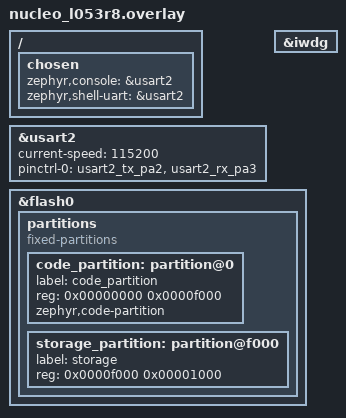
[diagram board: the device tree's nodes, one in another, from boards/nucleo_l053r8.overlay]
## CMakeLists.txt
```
cmake_minimum_required(VERSION 3.20.0)

if (BOARD STREQUAL "nucleo_l053r8")
  set(DTC_OVERLAY_FILE
      ${CMAKE_CURRENT_SOURCE_DIR}/boards/nucleo_l053r8.overlay
      ${CMAKE_CURRENT_SOURCE_DIR}/boards/nucleo_l053r8_app.overlay)
endif()

find_package(Zephyr REQUIRED HINTS $ENV{ZEPHYR_BASE})
project(led_threads)

# Add app sources explicitly
target_sources(app PRIVATE
  src/main.c
  src/supervisor.c
  src/recovery.c
  src/persist_state.c
  src/uart_commands.c
  src/watchdog_ctrl.c
)

# Allow #include "supervisor.h" etc without full path (autocomplete)
target_include_directories(app PRIVATE ${CMAKE_CURRENT_SOURCE_DIR}/src)
```

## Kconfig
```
menu "LED Threads Application"

config APP_WATCHDOG_BOOT_TIMEOUT_MS
	int "Boot watchdog timeout (ms)"
	default 8000
	range 100 60000
	help
	  Initial watchdog timeout applied during system startup. Use a large
	  value to cover expensive init sequences.

config APP_WATCHDOG_STEADY_TIMEOUT_MS
	int "Steady-state watchdog timeout (ms)"
	default 2000
	range 100 60000
	help
	  Watchdog timeout that the supervisor applies once the system has
	  reached its steady state.

config APP_WATCHDOG_RETUNE_DELAY_MS
	int "Delay before watchdog retune (ms)"
	default 5000
	range 0 60000
	help
	  Duration after boot before the watchdog is tightened to the
	  steady-state timeout.

config APP_RESET_WATCHDOG_THRESHOLD
	int "Watchdog reset storm threshold"
	default 3
	range 1 20
	help
	  Number of consecutive watchdog resets that triggers fallback mode.

config APP_HEALTH_LED_STALE_MS
	int "LED heartbeat stale threshold (ms)"
	default 1500
	range 100 10000
	help
	  Maximum allowed age of the LED thread heartbeat before it is
	  considered stale.

config APP_HEALTH_SYS_STALE_MS
	int "System heartbeat stale threshold (ms)"
	default 1500
	range 100 10000
	help
	  Maximum allowed age of the system heartbeat before it is
	  considered stale.

config APP_ENABLE_UART_COMMANDS
	bool "Enable UART command handler"
	default y
	help
	  Enable a minimal UART command parser for runtime configuration of
	  watchdog parameters. Disable if RAM usage is too tight.

config APP_SAFE_MODE_REBOOT_DELAY_MS
	int "Safe-mode auto reboot delay (ms)"
	default 60000
	range 0 300000
	help
	  When fallback (safe) mode is entered, schedule an automatic warm
	  reboot after this many milliseconds. Set to 0 to keep the system in
	  safe mode indefinitely.

endmenu

source "Kconfig.zephyr"
```

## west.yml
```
manifest:
  defaults:
    remote: zephyrproject-rtos
  remotes:
    - name: zephyrproject-rtos
      url-base: https://github.com/zephyrproject-rtos
  projects:
    - name: zephyr
      revision: v4.2.0
      import: true
  self:
    path: .
```

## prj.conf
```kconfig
# ==== Core stacks ====
CONFIG_MAIN_STACK_SIZE=1568
CONFIG_ISR_STACK_SIZE=1024
CONFIG_IDLE_STACK_SIZE=320

# ==== Storage / persistence ====
# Flash/NVS requires flash driver enabled explicitly on this part
CONFIG_FLASH=y
CONFIG_FLASH_PAGE_LAYOUT=y
CONFIG_FLASH_MAP=y
CONFIG_NVS=y

# ---- Console / Serial ----
CONFIG_CONSOLE=y
CONFIG_UART_CONSOLE=y
CONFIG_SERIAL=y
CONFIG_THREAD_NAME=y

# ---- Logging to UART (no printk routing) ----
CONFIG_LOG=y
CONFIG_LOG_BACKEND_UART=y
CONFIG_LOG_MODE_IMMEDIATE=y        # immediate = safest on tiny MCUs
CONFIG_LOG_DEFAULT_LEVEL=3

# Keep printk enabled if the board wants it, but don't route printk into LOG
CONFIG_LOG_PRINTK=n

# ---- Drivers ----
CONFIG_GPIO=y
CONFIG_HWINFO=y                    # for hwinfo_get_reset_cause()

#our code will control wdg, not default setup
CONFIG_WDT_DISABLE_AT_BOOT=y
CONFIG_WATCHDOG=y

# ---- Fault dump (replace any FATAL_EXCEPTION_DUMP usage) ----
CONFIG_FAULT_DUMP=1              

# Enable reboot & system management
CONFIG_REBOOT=y

# Application tuning
CONFIG_APP_WATCHDOG_BOOT_TIMEOUT_MS=8000
CONFIG_APP_WATCHDOG_STEADY_TIMEOUT_MS=2000
CONFIG_APP_WATCHDOG_RETUNE_DELAY_MS=5000
CONFIG_APP_RESET_WATCHDOG_THRESHOLD=3
CONFIG_APP_HEALTH_LED_STALE_MS=1500
CONFIG_APP_HEALTH_SYS_STALE_MS=1500
CONFIG_APP_ENABLE_UART_COMMANDS=n
CONFIG_APP_SAFE_MODE_REBOOT_DELAY_MS=60000

# Thread configuration
CONFIG_THREAD_MONITOR=y
CONFIG_THREAD_STACK_INFO=y

# Recovery + supervisor require event support
CONFIG_EVENTS=y
```

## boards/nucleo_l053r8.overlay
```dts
/{
	chosen{
		zephyr,console=&usart2;
		zephyr,shell-uart=&usart2;
	};
};
&usart2{ 
	status="okay"; current-speed = <115200>; 
	pinctrl-0 = < &usart2_tx_pa2 &usart2_rx_pa3>; pinctrl-names = "default";
};


/*Enable STM32 Independent Watchdog (IWDG)*/
&iwdg{
	status="okay";
};

&flash0 {
	partitions {
		compatible = "fixed-partitions";
		#address-cells = <1>;
		#size-cells = <1>;

		code_partition: partition@0 {
			label = "code_partition";
			reg = <0x00000000 0x0000f000>;
			zephyr,code-partition;
		};

		storage_partition: partition@f000 {
			label = "storage";
			reg = <0x0000f000 0x00001000>;
		};
	};
};
```

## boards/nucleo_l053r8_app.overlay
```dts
&code_partition {
	/delete-property/ zephyr,code-partition;
};

/ {
	chosen {
		zephyr,code-partition = &code_partition;
	};
};
```

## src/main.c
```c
/* main.c - NUCLEO-L053R8: LED + Heartbeat + Watchdog (STM32 IWDG) */
#include <zephyr/drivers/gpio.h>
#include <zephyr/drivers/hwinfo.h>
#include <zephyr/kernel.h>
#include <zephyr/logging/log.h>
#include <zephyr/sys/util.h>
#include <stdint.h>

#include "log_utils.h"
#include "persist_state.h"
#include "recovery.h"
#include "supervisor.h"
#include "uart_commands.h"
#include "watchdog_ctrl.h"

LOG_MODULE_REGISTER(app, LOG_LEVEL_INF);

/* -------- LED: via devicetree alias 'led0' -------- */
#define LED0_NODE DT_ALIAS(led0)
#if !DT_NODE_HAS_STATUS(LED0_NODE, okay)
#error "Unsupported board: led0 devicetree alias is not defined"
#endif
static const struct gpio_dt_spec led = GPIO_DT_SPEC_GET(LED0_NODE, gpios);

/* Optional reset cause printout */
static uint32_t log_reset_cause(void)
{
	uint32_t cause = 0;
	if (hwinfo_get_reset_cause(&cause) == 0) {
		if (cause & RESET_WATCHDOG) LOG_WRN("Reset cause: WATCHDOG");
		if (cause & RESET_SOFTWARE) LOG_WRN("Reset cause: SOFTWARE");
		if (cause & RESET_POR)      LOG_WRN("Reset cause: POWER-ON");
		hwinfo_clear_reset_cause();
	}
	return cause;
}

/* -------- Threads -------- */
K_THREAD_STACK_DEFINE(health_stack, 704);
static struct k_thread health_tid;

static void health_thread(void *p1, void *p2, void *p3)
{
	bool fallback_mode = (bool)(uintptr_t)p1;
	ARG_UNUSED(p2);
	ARG_UNUSED(p3);
	k_thread_name_set(k_current_get(),
			      fallback_mode ? "health (fallback)" : "health");

	int ret = gpio_pin_configure_dt(&led, GPIO_OUTPUT_INACTIVE);
	if (ret) {
		LOG_ERR("LED config failed: %d", ret);
		return;
	}

	if (fallback_mode) {
		LOG_EVT_SIMPLE(WRN, "SAFE_MODE", "LED_SLOW_BLINK");
	}

	const uint32_t led_period_ms = fallback_mode ? 1000U : 500U;
	const uint32_t heartbeat_period_ms = 1000U;
	uint32_t hb_elapsed = 0U;
	uint32_t heartbeat_counter = 0U;

	while (1) {
		ret = gpio_pin_toggle_dt(&led);
		if (ret) {
			LOG_ERR("LED toggle failed: %d", ret);
			k_msleep(1000);
			continue;
		}

		supervisor_notify_led_alive();

		hb_elapsed += led_period_ms;
		if (hb_elapsed >= heartbeat_period_ms) {
			hb_elapsed -= heartbeat_period_ms;
			supervisor_notify_system_alive();
			heartbeat_counter++;

		if ((heartbeat_counter % 10U) == 0U) {
			LOG_EVT(INF, "HEARTBEAT", "OK", "count=%u", heartbeat_counter);
		}
		}

		k_msleep(led_period_ms);
	}
}

void main(void)
{
	k_thread_name_set(k_current_get(), "main");
	LOG_EVT_SIMPLE(INF, "APP", "START");

	int ret = persist_state_init();
	if (ret) {
		LOG_ERR("Persistent state init failed: %d", ret);
	}

	uint32_t reset_cause = log_reset_cause();
	bool watchdog_reset = (reset_cause & RESET_WATCHDOG) != 0U;
	persist_state_record_boot(watchdog_reset);

	uint32_t consecutive = persist_state_get_consecutive_watchdog();
	if (consecutive != 0U) {
		LOG_EVT(WRN, "WATCHDOG", "RESET_HISTORY",
			"consecutive=%u,total=%u", consecutive, persist_state_get_total_watchdog());
	}

	bool fallback_mode = persist_state_is_fallback_active();
	if (fallback_mode) {
		LOG_EVT_SIMPLE(ERR, "SAFE_MODE", "ENTERED");
		persist_state_clear_watchdog_counter();
		LOG_EVT_SIMPLE(INF, "WATCHDOG", "COUNTER_CLEARED");
	}

	recovery_start();
	recovery_schedule_safe_mode_reboot(
		fallback_mode ? CONFIG_APP_SAFE_MODE_REBOOT_DELAY_MS : 0U);

	uint32_t boot_timeout_ms = CONFIG_APP_WATCHDOG_BOOT_TIMEOUT_MS;
	uint32_t steady_timeout_ms = persist_state_get_watchdog_override();
	if (steady_timeout_ms == 0U) {
		steady_timeout_ms = CONFIG_APP_WATCHDOG_STEADY_TIMEOUT_MS;
	}
	uint32_t retune_delay_ms = CONFIG_APP_WATCHDOG_RETUNE_DELAY_MS;

	if (fallback_mode) {
		steady_timeout_ms = MAX(steady_timeout_ms, boot_timeout_ms);
		retune_delay_ms = 0U;
	}

	ret = watchdog_ctrl_init(boot_timeout_ms);
	if (ret) {
		LOG_EVT(ERR, "WATCHDOG", "INIT_FAIL", "rc=%d", ret);
		LOG_EVT_SIMPLE(ERR, "RECOVERY", "WATCHDOG_INIT_FAIL");
		recovery_request(RECOVERY_REASON_WATCHDOG_INIT_FAIL);
		return;
	}

	LOG_EVT(INF, "WATCHDOG", "CONFIGURED",
		"boot_ms=%u,steady_ms=%u,retune_delay_ms=%u", boot_timeout_ms,
		steady_timeout_ms, retune_delay_ms);
	if (fallback_mode) {
		LOG_EVT_SIMPLE(WRN, "WATCHDOG", "RETUNE_DISABLED_SAFE_MODE");
	}

	k_thread_create(&health_tid, health_stack, K_THREAD_STACK_SIZEOF(health_stack),
			health_thread, (void *)(uintptr_t)fallback_mode,
			NULL, NULL, 5, 0, K_NO_WAIT);
	k_thread_name_set(&health_tid, fallback_mode ?
			       "Health Thread (fallback)" : "Health Thread");

	supervisor_start(steady_timeout_ms, retune_delay_ms, !fallback_mode);

	if (IS_ENABLED(CONFIG_APP_ENABLE_UART_COMMANDS)) {
		uart_commands_start(fallback_mode);
	}

	/* small delay to let logging flush before threads settle */
	k_msleep(120);

	LOG_EVT_SIMPLE(INF, "APP", "READY");

}
```

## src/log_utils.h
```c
#pragma once

#include <zephyr/logging/log.h>

/* Compact structured logging helpers.
 * Format: EVT,<tag>,<status>[,<kv pairs...>]
 */
#define LOG_EVT_SIMPLE(level, tag, status) \
	LOG_##level("EVT,%s,%s", tag, status)

#define LOG_EVT(level, tag, status, fmt, ...) \
	LOG_##level("EVT,%s,%s," fmt, tag, status, ##__VA_ARGS__)
```

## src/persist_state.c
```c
#include "persist_state.h"
#include "log_utils.h"

#include <errno.h>
#include <string.h>

#include <zephyr/device.h>
#include <zephyr/drivers/flash.h>
#include <zephyr/kernel.h>
#include <zephyr/logging/log.h>
#include <zephyr/storage/flash_map.h>
#include <zephyr/fs/nvs.h>

LOG_MODULE_REGISTER(persist_state, LOG_LEVEL_INF);

#define PERSIST_MAGIC 0x4C454452u /* 'LEDR' */
#define PERSIST_RECORD_ID 1

#define STORAGE_PARTITION_NODE DT_NODELABEL(storage_partition)
#define PERSIST_RETRY_LIMIT 3
#define PERSIST_RETRY_DELAY_MS 10

struct persist_blob {
	uint32_t magic;
	uint32_t consecutive_watchdog;
	uint32_t total_watchdog;
	uint32_t watchdog_override_ms;
};

static struct {
	struct nvs_fs fs;
	struct persist_blob blob;
	bool loaded;
} g_state;

static K_MUTEX_DEFINE(state_lock);

static int persist_commit_locked(void)
{
	int rc = nvs_write(&g_state.fs, PERSIST_RECORD_ID,
			   &g_state.blob, sizeof(g_state.blob));

	if (rc < 0) {
		LOG_ERR("Persistent write failed: %d", rc);
		LOG_EVT(ERR, "PERSIST", "WRITE_FAIL", "rc=%d", rc);
		return rc;
	}

	return 0;
}

static int init_fs_if_needed(void)
{
	if (g_state.loaded) {
		return 0;
	}

	const struct flash_area *fa = NULL;
	int rc = 0;

	for (int attempt = 1; attempt <= PERSIST_RETRY_LIMIT; ++attempt) {
		rc = flash_area_open(DT_FIXED_PARTITION_ID(STORAGE_PARTITION_NODE), &fa);
		if (rc == 0) {
			if (attempt > 1) {
				LOG_EVT(INF, "PERSIST", "FLASH_OPEN_RECOVERED", "attempt=%d", attempt);
			}
			break;
		}

		LOG_WRN("Failed to open storage partition (attempt %d/%d): %d",
			attempt, PERSIST_RETRY_LIMIT, rc);
		LOG_EVT(WRN, "PERSIST", "FLASH_OPEN_RETRY", "attempt=%d,rc=%d", attempt, rc);

		if (attempt < PERSIST_RETRY_LIMIT) {
			k_msleep(PERSIST_RETRY_DELAY_MS);
		}
	}

	if (rc != 0) {
		LOG_EVT(ERR, "PERSIST", "FLASH_OPEN_FAIL", "rc=%d", rc);
		return rc;
	}

	g_state.fs.flash_device = fa->fa_dev;
	if (!device_is_ready(g_state.fs.flash_device)) {
		LOG_ERR("Storage flash device not ready");
		LOG_EVT(ERR, "PERSIST", "FLASH_NOT_READY", "dev_id=%u",
			DT_FIXED_PARTITION_ID(STORAGE_PARTITION_NODE));
		flash_area_close(fa);
		return -EBUSY;
	}

	g_state.fs.offset = fa->fa_off;

	struct flash_pages_info page_info;
	rc = flash_get_page_info_by_offs(g_state.fs.flash_device,
					 g_state.fs.offset, &page_info);
	if (rc != 0) {
		LOG_ERR("flash_get_page_info_by_offs failed: %d", rc);
		LOG_EVT(ERR, "PERSIST", "FLASH_PAGE_INFO_FAIL", "rc=%d", rc);
		flash_area_close(fa);
		return rc;
	}

	g_state.fs.sector_size = page_info.size;
	g_state.fs.sector_count = fa->fa_size / page_info.size;

	flash_area_close(fa);

	for (int attempt = 1; attempt <= PERSIST_RETRY_LIMIT; ++attempt) {
		rc = nvs_mount(&g_state.fs);
		if (rc == 0) {
			if (attempt > 1) {
				LOG_EVT(INF, "PERSIST", "NVS_MOUNT_RECOVERED", "attempt=%d", attempt);
			}
			break;
		}

		LOG_WRN("Failed to mount NVS (attempt %d/%d): %d",
			attempt, PERSIST_RETRY_LIMIT, rc);
		LOG_EVT(WRN, "PERSIST", "NVS_MOUNT_RETRY", "attempt=%d,rc=%d", attempt, rc);

		if (attempt < PERSIST_RETRY_LIMIT) {
			k_msleep(PERSIST_RETRY_DELAY_MS);
		}
	}

	if (rc != 0) {
		LOG_EVT(ERR, "PERSIST", "NVS_MOUNT_FAIL", "rc=%d", rc);
		return rc;
	}

	struct persist_blob tmp;
	rc = nvs_read(&g_state.fs, PERSIST_RECORD_ID, &tmp, sizeof(tmp));
	if (rc == sizeof(tmp) && tmp.magic == PERSIST_MAGIC) {
		g_state.blob = tmp;
	} else {
		g_state.blob.magic = PERSIST_MAGIC;
		g_state.blob.consecutive_watchdog = 0U;
		g_state.blob.total_watchdog = 0U;
		g_state.blob.watchdog_override_ms = 0U;
		(void)persist_commit_locked();
	}

	g_state.loaded = true;
	LOG_INF("Persistent state loaded: consecutive=%u total=%u override=%u",
		g_state.blob.consecutive_watchdog,
		g_state.blob.total_watchdog,
		g_state.blob.watchdog_override_ms);
	return 0;
}

int persist_state_init(void)
{
	int rc;

	k_mutex_lock(&state_lock, K_FOREVER);
	rc = init_fs_if_needed();
	k_mutex_unlock(&state_lock);

	return rc;
}

void persist_state_record_boot(bool watchdog_reset)
{
	k_mutex_lock(&state_lock, K_FOREVER);

	if (init_fs_if_needed() != 0) {
		k_mutex_unlock(&state_lock);
		return;
	}

	if (watchdog_reset) {
		g_state.blob.consecutive_watchdog++;
		g_state.blob.total_watchdog++;
	} else if (g_state.blob.consecutive_watchdog != 0U) {
		g_state.blob.consecutive_watchdog = 0U;
	}

	(void)persist_commit_locked();
	k_mutex_unlock(&state_lock);
}

void persist_state_clear_watchdog_counter(void)
{
	k_mutex_lock(&state_lock, K_FOREVER);

	if (init_fs_if_needed() == 0 &&
	    g_state.blob.consecutive_watchdog != 0U) {
		g_state.blob.consecutive_watchdog = 0U;
		(void)persist_commit_locked();
	}

	k_mutex_unlock(&state_lock);
}

uint32_t persist_state_get_consecutive_watchdog(void)
{
	k_mutex_lock(&state_lock, K_FOREVER);
	uint32_t value = g_state.blob.consecutive_watchdog;
	k_mutex_unlock(&state_lock);
	return value;
}

uint32_t persist_state_get_total_watchdog(void)
{
	k_mutex_lock(&state_lock, K_FOREVER);
	uint32_t value = g_state.blob.total_watchdog;
	k_mutex_unlock(&state_lock);
	return value;
}

bool persist_state_is_fallback_active(void)
{
	return persist_state_get_consecutive_watchdog() >=
	       (uint32_t)CONFIG_APP_RESET_WATCHDOG_THRESHOLD;
}

uint32_t persist_state_get_watchdog_override(void)
{
	k_mutex_lock(&state_lock, K_FOREVER);
	uint32_t value = g_state.blob.watchdog_override_ms;
	k_mutex_unlock(&state_lock);
	return value;
}

int persist_state_set_watchdog_override(uint32_t timeout_ms)
{
	int rc = 0;

	k_mutex_lock(&state_lock, K_FOREVER);

	if (init_fs_if_needed() != 0) {
		k_mutex_unlock(&state_lock);
		return -EIO;
	}

	if (g_state.blob.watchdog_override_ms != timeout_ms) {
		g_state.blob.watchdog_override_ms = timeout_ms;
		rc = persist_commit_locked();
	}

	k_mutex_unlock(&state_lock);
	return rc;
}

#if defined(CONFIG_ZTEST)
void persist_state_test_reset(void)
{
	k_mutex_lock(&state_lock, K_FOREVER);

	if (init_fs_if_needed() == 0) {
		(void)nvs_clear(&g_state.fs);
	}

	memset(&g_state.fs, 0, sizeof(g_state.fs));
	memset(&g_state.blob, 0, sizeof(g_state.blob));
	g_state.loaded = false;
	k_mutex_unlock(&state_lock);
}

void persist_state_test_reload(void)
{
	k_mutex_lock(&state_lock, K_FOREVER);
	memset(&g_state.fs, 0, sizeof(g_state.fs));
	memset(&g_state.blob, 0, sizeof(g_state.blob));
	g_state.loaded = false;
	k_mutex_unlock(&state_lock);
}
#endif
```

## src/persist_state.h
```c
#pragma once

#include <stdbool.h>
#include <stdint.h>

int persist_state_init(void);
void persist_state_record_boot(bool watchdog_reset);
void persist_state_clear_watchdog_counter(void);

uint32_t persist_state_get_consecutive_watchdog(void);
uint32_t persist_state_get_total_watchdog(void);
bool persist_state_is_fallback_active(void);

uint32_t persist_state_get_watchdog_override(void);
int persist_state_set_watchdog_override(uint32_t timeout_ms);

#if defined(CONFIG_ZTEST)
void persist_state_test_reset(void);
void persist_state_test_reload(void);
#endif
```

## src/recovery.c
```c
#include <zephyr/kernel.h>
#include <zephyr/logging/log.h>
#include <zephyr/sys/reboot.h>
#include <zephyr/sys/util.h>
#include <limits.h>

#include "log_utils.h"
#include "recovery.h"

LOG_MODULE_REGISTER(recovery, LOG_LEVEL_INF);

/* Event used to signal recovery actions */
static struct k_event recovery_event;

K_THREAD_STACK_DEFINE(recovery_stack, 512);
static struct k_thread recovery_tid;

static K_MUTEX_DEFINE(safe_mode_lock);
static const int64_t SAFE_MODE_DEADLINE_INACTIVE = INT64_MIN;
static int64_t safe_mode_deadline = SAFE_MODE_DEADLINE_INACTIVE;
static uint32_t safe_mode_delay_ms;

static const char *recovery_reason_to_str(enum recovery_reason reason)
{
	switch (reason) {
	case RECOVERY_REASON_HEALTH_FAULT:
		return "persistent health fault";
	case RECOVERY_REASON_MANUAL_TRIGGER:
		return "manual recovery request";
	case RECOVERY_REASON_SAFE_MODE_TIMEOUT:
		return "safe-mode timeout";
	case RECOVERY_REASON_WATCHDOG_INIT_FAIL:
		return "watchdog init failure";
	default:
		return "unknown";
	}
}

void recovery_request(enum recovery_reason reason)
{
	if (reason < 0 || reason >= RECOVERY_REASON_COUNT) {
		LOG_WRN("Ignoring recovery request with invalid reason %d", reason);
		return;
	}

	LOG_EVT(WRN, "RECOVERY", "QUEUED", "reason=%d(%s)", reason,
		recovery_reason_to_str(reason));
	k_event_post(&recovery_event, BIT(reason));
}

static void handle_safe_mode_reboot(void)
{
	LOG_EVT_SIMPLE(WRN, "RECOVERY", "SAFE_MODE_TIMEOUT");
	LOG_EVT(WRN, "RECOVERY", "SAFE_MODE_REBOOT",
		"delay_ms=%u", safe_mode_delay_ms);
	sys_reboot(SYS_REBOOT_WARM);
}

static void recovery_thread(void *p1, void *p2, void *p3)
{
	ARG_UNUSED(p1); ARG_UNUSED(p2); ARG_UNUSED(p3);
	k_thread_name_set(k_current_get(), "recovery");

	while (1) {
		k_timeout_t wait = K_FOREVER;
		bool deadline_pending = false;

		k_mutex_lock(&safe_mode_lock, K_FOREVER);

			if (safe_mode_deadline != SAFE_MODE_DEADLINE_INACTIVE) {
			int64_t now = k_uptime_get();
			int64_t delta = safe_mode_deadline - now;

			if (delta <= 0) {
				safe_mode_deadline = SAFE_MODE_DEADLINE_INACTIVE;
				k_mutex_unlock(&safe_mode_lock);
				handle_safe_mode_reboot();
				continue;
			}

			if (delta > (int64_t)INT32_MAX) {
				delta = (int64_t)INT32_MAX;
			}

			wait = K_MSEC((uint32_t)delta);
			deadline_pending = true;
		}

		k_mutex_unlock(&safe_mode_lock);

		uint32_t events = k_event_wait(&recovery_event,
					       BIT_MASK(RECOVERY_REASON_COUNT),
					       true, wait);

		if (events == 0U) {
			/* timeout expired */
			if (deadline_pending) {
				continue;
			}
			/* No pending deadline; spurious timeout */
			continue;
		}

		if (events & BIT(RECOVERY_REASON_HEALTH_FAULT)) {
			LOG_EVT_SIMPLE(ERR, "RECOVERY", "HEALTH_FAULT");
			k_msleep(200);
			sys_reboot(SYS_REBOOT_WARM);
		}

		if (events & BIT(RECOVERY_REASON_MANUAL_TRIGGER)) {
			LOG_EVT_SIMPLE(WRN, "RECOVERY", "MANUAL_TRIGGER");
			k_msleep(200);
			sys_reboot(SYS_REBOOT_WARM);
		}

		if (events & BIT(RECOVERY_REASON_SAFE_MODE_TIMEOUT)) {
			k_mutex_lock(&safe_mode_lock, K_FOREVER);
			safe_mode_deadline = SAFE_MODE_DEADLINE_INACTIVE;
			k_mutex_unlock(&safe_mode_lock);
			handle_safe_mode_reboot();
		}

		if (events & BIT(RECOVERY_REASON_WATCHDOG_INIT_FAIL)) {
			LOG_EVT_SIMPLE(ERR, "RECOVERY", "WATCHDOG_INIT_REBOOT");
			k_msleep(200);
			sys_reboot(SYS_REBOOT_WARM);
		}
	}
}

void recovery_start(void)
{
	k_event_init(&recovery_event);
	k_thread_create(&recovery_tid, recovery_stack,
			K_THREAD_STACK_SIZEOF(recovery_stack),
			recovery_thread, NULL, NULL, NULL,
			5, 0, K_NO_WAIT);
}

void recovery_schedule_safe_mode_reboot(uint32_t delay_ms)
{
	k_mutex_lock(&safe_mode_lock, K_FOREVER);

	if (delay_ms == 0U) {
		bool was_scheduled = (safe_mode_deadline != SAFE_MODE_DEADLINE_INACTIVE);

		safe_mode_deadline = SAFE_MODE_DEADLINE_INACTIVE;
		safe_mode_delay_ms = 0U;
		k_mutex_unlock(&safe_mode_lock);

		if (was_scheduled) {
			LOG_EVT_SIMPLE(INF, "RECOVERY", "SAFE_MODE_REBOOT_CANCELLED");
			k_wakeup(&recovery_tid);
		}
		return;
	}

	safe_mode_deadline = k_uptime_get() + (int64_t)delay_ms;
	safe_mode_delay_ms = delay_ms;
	k_mutex_unlock(&safe_mode_lock);

	LOG_EVT(INF, "RECOVERY", "SAFE_MODE_REBOOT_SCHEDULED",
		"delay_ms=%u", delay_ms);
	k_wakeup(&recovery_tid);
}
```

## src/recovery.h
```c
#pragma once

#include <zephyr/kernel.h>

enum recovery_reason {
	RECOVERY_REASON_HEALTH_FAULT = 0,
	RECOVERY_REASON_MANUAL_TRIGGER,
	RECOVERY_REASON_SAFE_MODE_TIMEOUT,
	RECOVERY_REASON_WATCHDOG_INIT_FAIL,
	RECOVERY_REASON_COUNT
};

void recovery_start(void);
void recovery_request(enum recovery_reason reason);
void recovery_schedule_safe_mode_reboot(uint32_t delay_ms);
```

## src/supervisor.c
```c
#include <errno.h>

#include <zephyr/kernel.h>
#include <zephyr/logging/log.h>
#include <zephyr/sys/atomic.h>
#include <zephyr/sys/time_units.h>
#include <zephyr/sys/util.h>
#include <limits.h>
#include <string.h>

#include "log_utils.h"
#include "persist_state.h"
#include "recovery.h"
#include "supervisor.h"
#include "watchdog_ctrl.h"

LOG_MODULE_REGISTER(supervisor, LOG_LEVEL_INF);

#if defined(CONFIG_ZTEST)
#define SUPERVISOR_PERIOD_MS 50U
#define SUPERVISOR_BOOT_GRACE_MS 150U
#else
#define SUPERVISOR_PERIOD_MS 1000U
#define SUPERVISOR_BOOT_GRACE_MS 3000U
#endif
#define SUPERVISOR_MAX_FAILURES 3U

K_THREAD_STACK_DEFINE(supervisor_stack, 672);
static struct k_thread supervisor_tid;
static atomic_t led_last_seen = ATOMIC_INIT(0);
static atomic_t sys_last_seen = ATOMIC_INIT(0);
static int64_t supervisor_boot_ts;
static bool watchdog_counter_cleared;
#if defined(CONFIG_ZTEST)
static bool supervisor_thread_started;
#endif

struct watchdog_cfg {
	uint32_t desired_timeout_ms;
	uint32_t retune_delay_ms;
	int64_t retune_ready_ts;
	bool monitor_led;
	bool retune_pending;
	bool retune_done_once;
	bool retune_failed_logged;
};

static struct watchdog_cfg wd_cfg;
static K_MUTEX_DEFINE(cfg_lock);

static void update_retune_schedule_locked(bool apply_immediately)
{
	int64_t now = k_uptime_get();

	wd_cfg.retune_ready_ts = now + (apply_immediately ? 0 : (int64_t)wd_cfg.retune_delay_ms);
	wd_cfg.retune_pending = (wd_cfg.desired_timeout_ms != watchdog_ctrl_get_timeout());
	if (!wd_cfg.retune_pending) {
		wd_cfg.retune_done_once = true;
	}
	wd_cfg.retune_failed_logged = false;
}

static void snapshot_watchdog_cfg(struct watchdog_cfg *out_cfg)
{
	k_mutex_lock(&cfg_lock, K_FOREVER);
	*out_cfg = wd_cfg;
	k_mutex_unlock(&cfg_lock);
}

static bool feed_watchdog(const char *context, uint32_t *fail_count)
{
	int ret = watchdog_ctrl_feed();

	if (ret == 0) {
		return true;
	}

	if (ret == -EBUSY) {
		LOG_DBG("Watchdog feed skipped (%s): disabled", context);
		return false;
	}

	if (ret == -EAGAIN) {
		LOG_WRN("Watchdog feed unavailable (%s)", context);
		return false;
	}

	LOG_EVT(ERR, "WATCHDOG", "FEED_FAIL", "context=%s,rc=%d", context, ret);

	if (fail_count != NULL) {
		(*fail_count)++;
	}

	return false;
}

struct health_status {
	bool led_ok;
	bool hb_ok;
	uint32_t led_age;
	uint32_t hb_age;
};

static struct health_status sample_health(const struct watchdog_cfg *cfg, uint32_t now32)
{
	struct health_status status = {
		.led_ok = true,
		.hb_ok = false,
		.led_age = 0U,
		.hb_age = 0U,
	};

	uint32_t hb_last = atomic_get(&sys_last_seen);
	if (hb_last == 0U) {
		status.hb_ok = false;
		status.hb_age = UINT32_MAX;
	} else {
		uint32_t age = now32 - hb_last;
		status.hb_age = age;
		status.hb_ok = age <= CONFIG_APP_HEALTH_SYS_STALE_MS;
	}

	if (!cfg->monitor_led) {
		status.led_ok = true;
		status.led_age = 0U;
		return status;
	}

	uint32_t led_last = atomic_get(&led_last_seen);
	if (led_last == 0U) {
		status.led_ok = false;
		status.led_age = UINT32_MAX;
	} else {
		uint32_t age = now32 - led_last;
		status.led_age = age;
		status.led_ok = age <= CONFIG_APP_HEALTH_LED_STALE_MS;
	}

	return status;
}

void supervisor_notify_led_alive(void)
{
	atomic_set(&led_last_seen, k_uptime_get_32());
}

void supervisor_notify_system_alive(void)
{
	atomic_set(&sys_last_seen, k_uptime_get_32());
}

static void attempt_watchdog_retune(const struct watchdog_cfg *cfg, int64_t now)
{
	if (!cfg->retune_pending || now < cfg->retune_ready_ts) {
		return;
	}

	int rc = watchdog_ctrl_retune(cfg->desired_timeout_ms);

	if (rc == 0) {
		LOG_EVT(INF, "WATCHDOG", "RETUNED", "timeout_ms=%u", cfg->desired_timeout_ms);
		k_mutex_lock(&cfg_lock, K_FOREVER);
		wd_cfg.retune_pending = false;
		wd_cfg.retune_done_once = true;
		wd_cfg.retune_failed_logged = false;
		k_mutex_unlock(&cfg_lock);
		persist_state_clear_watchdog_counter();
		watchdog_counter_cleared = true;
		return;
	}

	if (rc == -ENOTSUP || rc == -ENOTTY) {
		if (!cfg->retune_failed_logged) {
			LOG_EVT(WRN, "WATCHDOG", "RETUNE_NOT_SUPPORTED", "rc=%d", rc);
		}
		k_mutex_lock(&cfg_lock, K_FOREVER);
		wd_cfg.retune_pending = false;
		wd_cfg.retune_done_once = true;
		wd_cfg.retune_failed_logged = true;
		k_mutex_unlock(&cfg_lock);
		return;
	}

	LOG_EVT(WRN, "WATCHDOG", "RETUNE_DEFERRED", "rc=%d", rc);
	k_mutex_lock(&cfg_lock, K_FOREVER);
	wd_cfg.retune_ready_ts = now + SUPERVISOR_PERIOD_MS;
	k_mutex_unlock(&cfg_lock);
}

static void supervisor_thread(void *p1, void *p2, void *p3)
{
	ARG_UNUSED(p1);
	ARG_UNUSED(p2);
	ARG_UNUSED(p3);

	k_thread_name_set(k_current_get(), "supervisor");

	uint32_t fail_count = 0;

	while (1) {
		int64_t now = k_uptime_get();
		uint32_t now32 = (uint32_t)now;
		struct watchdog_cfg cfg;

		snapshot_watchdog_cfg(&cfg);
		attempt_watchdog_retune(&cfg, now);

		struct health_status health = sample_health(&cfg, now32);
		bool in_boot_grace = (now - supervisor_boot_ts) < SUPERVISOR_BOOT_GRACE_MS;

		if (!watchdog_counter_cleared && cfg.retune_done_once && !in_boot_grace &&
		    health.led_ok && health.hb_ok) {
			persist_state_clear_watchdog_counter();
			watchdog_counter_cleared = true;
		}

		if (in_boot_grace) {
			if (watchdog_ctrl_is_enabled()) {
				(void)feed_watchdog("boot grace", NULL);
			}
			fail_count = 0;
		} else if (health.led_ok && health.hb_ok) {
			if (watchdog_ctrl_is_enabled()) {
				bool fed = feed_watchdog("steady-state", &fail_count);

				if (fed) {
					fail_count = 0;
				} else if (fail_count >= SUPERVISOR_MAX_FAILURES) {
					LOG_ERR("Repeated watchdog feed failures -- requesting recovery");
					recovery_request(RECOVERY_REASON_HEALTH_FAULT);
					fail_count = 0;
				}
			} else {
				fail_count = 0;
			}
		} else {
			fail_count++;
			const char *led_status = cfg.monitor_led ? (health.led_ok ? "ok" : "stale") : "disabled";
			LOG_EVT(WRN, "HEALTH", "DEGRADED",
				"fail=%u,led=%s,led_age_ms=%u,hb=%s,hb_age_ms=%u",
				fail_count,
				led_status,
				cfg.monitor_led ? health.led_age : 0U,
				health.hb_ok ? "ok" : "stale",
				health.hb_age);

			if (fail_count >= SUPERVISOR_MAX_FAILURES) {
				LOG_EVT_SIMPLE(ERR, "HEALTH", "RECOVERY_REQUEST");
				recovery_request(RECOVERY_REASON_HEALTH_FAULT);
				fail_count = 0;
			}
		}

		k_msleep(SUPERVISOR_PERIOD_MS);
	}
}

void supervisor_start(uint32_t steady_timeout_ms, uint32_t retune_delay_ms, bool monitor_led)
{
	supervisor_boot_ts = k_uptime_get();
	watchdog_counter_cleared = false;
	atomic_set(&sys_last_seen, k_uptime_get_32());
	if (!monitor_led) {
		atomic_set(&led_last_seen, k_uptime_get_32());
	}

	k_mutex_lock(&cfg_lock, K_FOREVER);
	wd_cfg.desired_timeout_ms = steady_timeout_ms;
	wd_cfg.retune_delay_ms = retune_delay_ms;
	wd_cfg.monitor_led = monitor_led;
	wd_cfg.retune_done_once = false;
	wd_cfg.retune_pending = true;
	wd_cfg.retune_failed_logged = false;
	update_retune_schedule_locked(false);
	k_mutex_unlock(&cfg_lock);

	k_thread_create(&supervisor_tid, supervisor_stack,
			K_THREAD_STACK_SIZEOF(supervisor_stack), supervisor_thread,
			NULL, NULL, NULL, 6, 0, K_NO_WAIT);
#if defined(CONFIG_ZTEST)
	supervisor_thread_started = true;
#endif
}

int supervisor_request_watchdog_target(uint32_t timeout_ms, bool apply_immediately)
{
	k_mutex_lock(&cfg_lock, K_FOREVER);
	wd_cfg.desired_timeout_ms = timeout_ms;
	wd_cfg.retune_done_once = false;
	watchdog_counter_cleared = false;
	update_retune_schedule_locked(apply_immediately);
	k_mutex_unlock(&cfg_lock);
	return 0;
}

uint32_t supervisor_get_watchdog_target(void)
{
	k_mutex_lock(&cfg_lock, K_FOREVER);
	uint32_t value = wd_cfg.desired_timeout_ms;
	k_mutex_unlock(&cfg_lock);
	return value;
}

void supervisor_request_manual_recovery(void)
{
	recovery_request(RECOVERY_REASON_MANUAL_TRIGGER);
}

#if defined(CONFIG_ZTEST)
void supervisor_test_reset(void)
{
	if (supervisor_thread_started) {
		k_thread_abort(&supervisor_tid);
		supervisor_thread_started = false;
	}

	atomic_set(&led_last_seen, 0);
	atomic_set(&sys_last_seen, 0);
	watchdog_counter_cleared = false;
	supervisor_boot_ts = 0;

	k_mutex_lock(&cfg_lock, K_FOREVER);
	memset(&wd_cfg, 0, sizeof(wd_cfg));
	k_mutex_unlock(&cfg_lock);
}
#endif
```

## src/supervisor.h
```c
#pragma once

#include <stdbool.h>
#include <stdint.h>

void supervisor_start(uint32_t steady_timeout_ms, uint32_t retune_delay_ms,
                      bool monitor_led);
void supervisor_notify_led_alive(void);
void supervisor_notify_system_alive(void);
int supervisor_request_watchdog_target(uint32_t timeout_ms, bool apply_immediately);
uint32_t supervisor_get_watchdog_target(void);
void supervisor_request_manual_recovery(void);

#if defined(CONFIG_ZTEST)
void supervisor_test_reset(void);
#endif
```

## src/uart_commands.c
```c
#include "uart_commands.h"

#include <ctype.h>
#include <errno.h>
#include <stdlib.h>
#include <string.h>

#include <zephyr/device.h>
#include <zephyr/drivers/uart.h>
#include <zephyr/kernel.h>
#include <zephyr/logging/log.h>

#include "log_utils.h"
#include "persist_state.h"
#include "supervisor.h"
#include "watchdog_ctrl.h"

LOG_MODULE_REGISTER(uart_cmd, LOG_LEVEL_INF);

#if IS_ENABLED(CONFIG_APP_ENABLE_UART_COMMANDS)

#define CMD_STACK_SIZE 288
#define CMD_THREAD_PRIORITY 9

K_THREAD_STACK_DEFINE(cmd_stack, CMD_STACK_SIZE);
static struct k_thread cmd_thread;
static bool cmd_fallback_mode;
static const struct device *uart_dev;

static void print_status(void)
{
	uint32_t boot_timeout = CONFIG_APP_WATCHDOG_BOOT_TIMEOUT_MS;
	uint32_t steady_target = supervisor_get_watchdog_target();
	uint32_t current_hw = watchdog_ctrl_get_timeout();
	uint32_t override = persist_state_get_watchdog_override();
	uint32_t consecutive = persist_state_get_consecutive_watchdog();

	LOG_EVT(INF, "TELEMETRY", "WATCHDOG_STATUS",
		"boot_ms=%u,current_ms=%u,target_ms=%u,override_ms=%u,fallback=%s",
		boot_timeout, current_hw, steady_target, override,
		cmd_fallback_mode ? "yes" : "no");
	if (consecutive != 0U) {
		LOG_EVT(INF, "TELEMETRY", "WATCHDOG_RESETS", "count=%u", consecutive);
	}
}

static void apply_timeout(uint32_t timeout_ms)
{
	if (timeout_ms < 100U || timeout_ms > 60000U) {
		LOG_WRN("Timeout %u ms out of range (100-60000)", timeout_ms);
		return;
	}

	int rc = persist_state_set_watchdog_override(timeout_ms);
	if (rc < 0) {
		LOG_ERR("Failed to persist watchdog override: %d", rc);
		return;
	}

	supervisor_request_watchdog_target(timeout_ms, true);
	LOG_EVT(INF, "WATCHDOG", "OVERRIDE_SET", "timeout_ms=%u", timeout_ms);
}

static void clear_override(void)
{
	int rc = persist_state_set_watchdog_override(0U);
	if (rc < 0) {
		LOG_ERR("Failed to clear watchdog override: %d", rc);
		return;
	}

	supervisor_request_watchdog_target(CONFIG_APP_WATCHDOG_STEADY_TIMEOUT_MS, true);
	LOG_EVT(INF, "WATCHDOG", "OVERRIDE_CLEARED",
		"steady_ms=%u", CONFIG_APP_WATCHDOG_STEADY_TIMEOUT_MS);
}

static void handle_line(const char *line)
{
	while (isspace((unsigned char)*line)) {
		line++;
	}

	if (*line == '\0') {
		return;
	}

	if (strncmp(line, "wdg", 3) != 0) {
		LOG_EVT(WRN, "UART_CMD", "UNKNOWN", "cmd=%s", line);
		return;
	}

	line += 3;
	while (isspace((unsigned char)*line)) {
		line++;
	}

	if (*line == '?') {
		print_status();
		return;
	}

	if (strncmp(line, "clear", 5) == 0) {
		clear_override();
		return;
	}

	errno = 0;
	char *end = NULL;
	unsigned long val = strtoul(line, &end, 10);
	if (errno || end == line) {
		LOG_EVT(WRN, "UART_CMD", "PARSE_FAIL", "arg=%s", line);
		return;
	}

	if (*end != '\0' && !isspace((unsigned char)*end)) {
		LOG_EVT(WRN, "UART_CMD", "GARBAGE_TRAILING", "suffix=%s", end);
		return;
	}

	apply_timeout((uint32_t)val);
}

static void command_thread(void *p1, void *p2, void *p3)
{
	ARG_UNUSED(p1);
	ARG_UNUSED(p2);
	ARG_UNUSED(p3);

	k_thread_name_set(k_current_get(), "uart_cmd");

	char buffer[48];
	size_t len = 0U;

	LOG_EVT(INF, "UART_CMD", "READY",
		"fallback=%s", cmd_fallback_mode ? "yes" : "no");

	while (1) {
		uint8_t ch;
		int rc = uart_poll_in(uart_dev, &ch);
		if (rc != 0) {
			k_sleep(K_MSEC(20));
			continue;
		}

		if (ch == '\r' || ch == '\n') {
			if (len > 0U) {
				buffer[len] = '\0';
				handle_line(buffer);
				len = 0U;
			}
			continue;
		}

		if (len < sizeof(buffer) - 1U) {
			buffer[len++] = (char)ch;
		}
	}
}

void uart_commands_start(bool fallback_mode)
{
	cmd_fallback_mode = fallback_mode;

	uart_dev = DEVICE_DT_GET(DT_CHOSEN(zephyr_console));
	if (!device_is_ready(uart_dev)) {
		LOG_ERR("Console UART not ready; disabling command handler");
		return;
	}

	k_thread_create(&cmd_thread, cmd_stack, K_THREAD_STACK_SIZEOF(cmd_stack),
			command_thread, NULL, NULL, NULL, CMD_THREAD_PRIORITY, 0,
			K_NO_WAIT);
}

#else /* CONFIG_APP_ENABLE_UART_COMMANDS */

void uart_commands_start(bool fallback_mode)
{
	ARG_UNUSED(fallback_mode);
}

#endif
```

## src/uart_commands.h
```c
#pragma once

#include <stdbool.h>

void uart_commands_start(bool fallback_mode);
```

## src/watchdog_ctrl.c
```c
#include <zephyr/device.h>
#include <zephyr/devicetree.h>
#include <zephyr/drivers/watchdog.h>
#include <zephyr/kernel.h>
#include <zephyr/logging/log.h>
#include <zephyr/sys/atomic.h>
#include <zephyr/sys/time_units.h>
#include <zephyr/sys/util.h>

#if DT_NODE_HAS_COMPAT(DT_NODELABEL(iwdg), st_stm32_iwdg)
#include <stm32_ll_iwdg.h>
#endif

#include "watchdog_ctrl.h"

LOG_MODULE_REGISTER(watchdog_ctrl, LOG_LEVEL_INF);

#define WDT_NODE DT_NODELABEL(iwdg)
BUILD_ASSERT(DT_NODE_HAS_STATUS(WDT_NODE, okay), "IWDG node must be available");

static const struct device *const wdt = DEVICE_DT_GET(WDT_NODE);
static atomic_t feed_enabled = ATOMIC_INIT(1);
static int wdt_channel_id = -1;
static uint32_t current_timeout_ms;

#if DT_NODE_HAS_COMPAT(DT_NODELABEL(iwdg), st_stm32_iwdg)
#ifndef LSI_VALUE
#define LSI_VALUE 32000U
#endif

#define IWDG_RELOAD_MAX 0x0FFFU
#define IWDG_PRESCALER_MIN 4U
#define IWDG_PRESCALER_MAX 256U
#define IWDG_SR_UPDATE_TIMEOUT_MS (6U * IWDG_PRESCALER_MAX * MSEC_PER_SEC / LSI_VALUE)

static int stm32_iwdg_compute(uint32_t timeout_ms, uint32_t *prescaler, uint32_t *reload)
{
	uint64_t timeout_us = (uint64_t)timeout_ms * USEC_PER_MSEC;
	uint32_t divider = IWDG_PRESCALER_MIN;
	uint32_t shift = 0U;
	uint32_t ticks = (uint64_t)timeout_us * LSI_VALUE / USEC_PER_SEC;

	while ((ticks / divider) > IWDG_RELOAD_MAX) {
		shift++;
		divider = IWDG_PRESCALER_MIN << shift;
		if (divider > IWDG_PRESCALER_MAX) {
			return -EINVAL;
		}
	}

	uint32_t value = ticks / divider;
	if (value == 0U) {
		return -EINVAL;
	}

	value -= 1U;
	if (value > IWDG_RELOAD_MAX) {
		value = IWDG_RELOAD_MAX;
	}

	*prescaler = shift;
	*reload = value;
	return 0;
}

static int stm32_iwdg_retune_hw(uint32_t timeout_ms)
{
	uint32_t prescaler = 0U;
	uint32_t reload = 0U;
	int rc = stm32_iwdg_compute(timeout_ms, &prescaler, &reload);
	if (rc != 0) {
		return rc;
	}

	LL_IWDG_EnableWriteAccess(IWDG);
	LL_IWDG_SetPrescaler(IWDG, prescaler);
	LL_IWDG_SetReloadCounter(IWDG, reload);

	uint32_t start = k_uptime_get_32();
	while (LL_IWDG_IsReady(IWDG) == 0U) {
		if ((k_uptime_get_32() - start) > IWDG_SR_UPDATE_TIMEOUT_MS) {
			return -EAGAIN;
		}
	}

	LL_IWDG_ReloadCounter(IWDG);
	return 0;
}
#endif

int watchdog_ctrl_init(uint32_t timeout_ms)
{
	if (!device_is_ready(wdt)) {
		LOG_ERR("Watchdog device not ready");
		return -ENODEV;
	}

	struct wdt_timeout_cfg cfg = {
		.window = {
			.min = 0,
			.max = timeout_ms,
		},
		.callback = NULL,
		.flags = WDT_FLAG_RESET_SOC,
	};

	if (wdt_channel_id < 0) {
		int ret = wdt_install_timeout(wdt, &cfg);
		if (ret < 0) {
			LOG_ERR("Failed to install watchdog timeout: %d", ret);
			return ret;
		}

		wdt_channel_id = ret;
	}

	int ret = wdt_setup(wdt, 0);
	if (ret) {
		LOG_ERR("Watchdog setup failed: %d", ret);
		return ret;
	}

	current_timeout_ms = timeout_ms;
	return watchdog_ctrl_feed();
}

int watchdog_ctrl_feed(void)
{
	if (wdt_channel_id < 0) {
		return -EAGAIN;
	}

	if (!atomic_get(&feed_enabled)) {
		return -EBUSY;
	}

	return wdt_feed(wdt, wdt_channel_id);
}

void watchdog_ctrl_set_enabled(bool enable)
{
	atomic_set(&feed_enabled, enable ? 1 : 0);

	if (enable) {
		int ret = watchdog_ctrl_feed();
		if (ret && ret != -EBUSY) {
			LOG_WRN("Watchdog feed after enabling failed: %d", ret);
		}
	}
}

bool watchdog_ctrl_is_enabled(void)
{
	return atomic_get(&feed_enabled) != 0;
}

int watchdog_ctrl_retune(uint32_t timeout_ms)
{
	if (wdt_channel_id < 0) {
		return -EAGAIN;
	}

	if (timeout_ms == 0U) {
		return -EINVAL;
	}

	if (timeout_ms == current_timeout_ms) {
		return 0;
	}

#if DT_NODE_HAS_COMPAT(DT_NODELABEL(iwdg), st_stm32_iwdg)
	int rc = stm32_iwdg_retune_hw(timeout_ms);
	if (rc == 0) {
		current_timeout_ms = timeout_ms;
	}
	return rc;
#else
	ARG_UNUSED(timeout_ms);
	return -ENOTSUP;
#endif
}

uint32_t watchdog_ctrl_get_timeout(void)
{
	return current_timeout_ms;
}
```

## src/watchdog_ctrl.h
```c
#pragma once

#include <stdbool.h>
#include <stdint.h>

int watchdog_ctrl_init(uint32_t timeout_ms);
int watchdog_ctrl_feed(void);
void watchdog_ctrl_set_enabled(bool enable);
bool watchdog_ctrl_is_enabled(void);
int watchdog_ctrl_retune(uint32_t timeout_ms);
uint32_t watchdog_ctrl_get_timeout(void);
```
